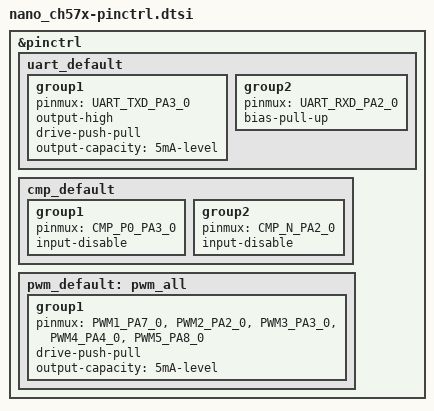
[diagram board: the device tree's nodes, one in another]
/*
 * SPDX-FileCopyrightText: 2026 SMILE (smile.eu)
 * SPDX-License-Identifier: Apache-2.0
 */

#include <zephyr/dt-bindings/pinctrl/ch570-pinctrl.h>

&pinctrl {
	uart_default: uart_default {
		group1 {
			pinmux = <UART_TXD_PA3_0>;
			output-high;
			drive-push-pull;
			output-capacity = "5mA-level";
		};

		group2 {
			pinmux = <UART_RXD_PA2_0>;
			bias-pull-up;
		};
	};

	cmp_default: cmp_default {
		group1 {
			pinmux = <CMP_P0_PA3_0>;
			input-disable;
		};

		group2 {
			pinmux = <CMP_N_PA2_0>;
			input-disable;
		};
	};

	pwm_default: pwm_all {
		group1 {
			pinmux = <PWM1_PA7_0>,
				 <PWM2_PA2_0>,
				 <PWM3_PA3_0>,
				 <PWM4_PA4_0>,
				 <PWM5_PA8_0>;
			drive-push-pull;
			output-capacity = "5mA-level";
		};
	};
};
